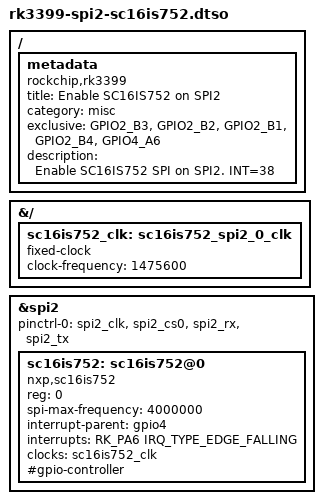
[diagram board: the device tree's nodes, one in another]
/dts-v1/;
/plugin/;

#include <dt-bindings/gpio/gpio.h>
#include <dt-bindings/pinctrl/rockchip.h>
#include <dt-bindings/interrupt-controller/irq.h>

/{
	metadata {
		title = "Enable SC16IS752 on SPI2";
		compatible = "rockchip,rk3399";
		category = "misc";
		exclusive = "GPIO2_B3", "GPIO2_B2", "GPIO2_B1", "GPIO2_B4", "GPIO4_A6";
		description = "Enable SC16IS752 SPI on SPI2.
INT=38";
	};
};

&{/} {
	sc16is752_clk: sc16is752_spi2_0_clk {
		compatible = "fixed-clock";
		clock-frequency = <1475600>;
		#clock-cells = <0>;
	};
};

&spi2 {
	status = "okay";
	pinctrl-names = "default";
	pinctrl-0 = <&spi2_clk &spi2_cs0 &spi2_rx &spi2_tx>;

	#address-cells = <1>;
	#size-cells = <0>;

	sc16is752: sc16is752@0 {
		compatible = "nxp,sc16is752";
		reg = <0>;
		spi-max-frequency = <4000000>;

		interrupt-parent = <&gpio4>;
		interrupts = <RK_PA6 IRQ_TYPE_EDGE_FALLING>;

		clocks = <&sc16is752_clk>;
		#gpio-controller;
		#gpio-cells = <2>;
	};
};
